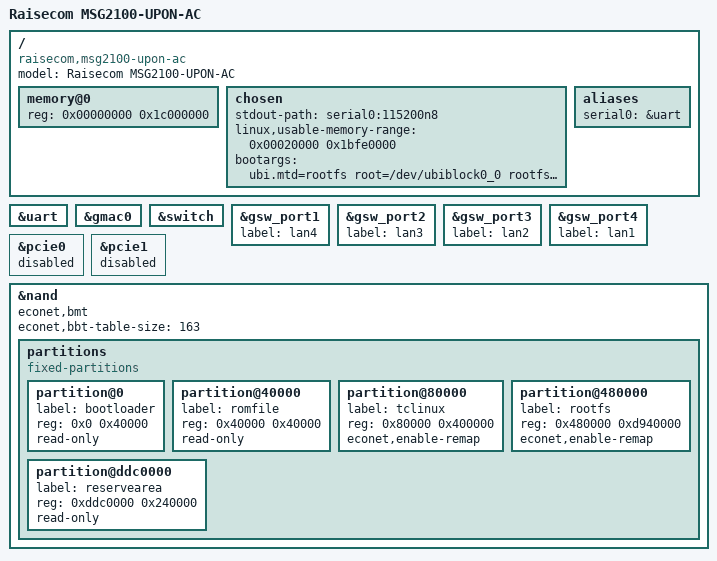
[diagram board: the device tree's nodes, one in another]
// SPDX-License-Identifier: GPL-2.0-or-later
/*
 * Raisecom MSG2100-UPON-AC (China Mobile, F.20/SC12)
 * SoC: Econet/Airoha EN7528HU (MIPS 1004Kc, LE, 900MHz)
 * RAM: 512MB DDR3L (Samsung K4B4G1646B)
 * Flash: Micron MT29F2G01 256MB SPI NAND (2048+64B pages, 128KB blocks)
 * WiFi: none (pure wired: 1x GPON + 4x GE)
 * UART: 115200 8N1, console on ttyS0 (Econet UART @ 0x1fbf0000)
 */

/dts-v1/;

#include "en7528.dtsi"

/ {
	model = "Raisecom MSG2100-UPON-AC";
	compatible = "raisecom,msg2100-upon-ac", "econet,en7528";

	memory@0 {
		device_type = "memory";
		reg = <0x00000000 0x1c000000>;	/* 448MB (top 64MB is NAND/peripherals) */
	};

	chosen {
		stdout-path = "serial0:115200n8";
		linux,usable-memory-range = <0x00020000 0x1bfe0000>;
		bootargs = "ubi.mtd=rootfs root=/dev/ubiblock0_0 rootfstype=squashfs";
	};

	aliases {
		serial0 = &uart;
	};

};

&uart {
	status = "okay";
};

&gmac0 {
	status = "okay";
};

&switch {
	status = "okay";
};

&gsw_port1 {
	label = "lan4";
	status = "okay";
};

&gsw_port2 {
	label = "lan3";
	status = "okay";
};

&gsw_port3 {
	label = "lan2";
	status = "okay";
};

&gsw_port4 {
	label = "lan1";
	status = "okay";
};

/* No WiFi / PCIe on this wired-only device */
&pcie0 {
	status = "disabled";
};

&pcie1 {
	status = "disabled";
};

&nand {
	status = "okay";
	econet,bmt;
	econet,bbt-table-size = <163>;

	partitions {
		compatible = "fixed-partitions";
		#address-cells = <1>;
		#size-cells = <1>;

		partition@0 {
			label = "bootloader";
			reg = <0x0 0x40000>;
			read-only;
		};

		partition@40000 {
			label = "romfile";
			reg = <0x40000 0x40000>;
			read-only;
		};

		partition@80000 {
			label = "tclinux";
			reg = <0x80000 0x400000>;
			econet,enable-remap;
		};

		partition@480000 {
			label = "rootfs";
			reg = <0x480000 0xd940000>;
			econet,enable-remap;
		};

		partition@ddc0000 {
			label = "reservearea";
			reg = <0xddc0000 0x240000>;
			read-only;
		};
	};
};
